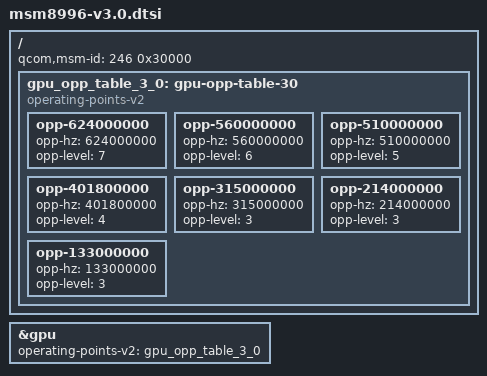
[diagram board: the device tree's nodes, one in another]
// SPDX-License-Identifier: BSD-3-Clause
/*
 * Copyright (c) 2021, Konrad Dybcio <konrad.dybcio@somainline.org>
 * Adapted for Sony Xperia X Performance (dora) MSM8996 v3.0 S1 bootloader support.
 */

/ {
	qcom,msm-id = <246 0x30000>;

	gpu_opp_table_3_0: gpu-opp-table-30 {
		compatible = "operating-points-v2";

		opp-624000000 {
			opp-hz = /bits/ 64 <624000000>;
			opp-level = <7>;
		};
		opp-560000000 {
			opp-hz = /bits/ 64 <560000000>;
			opp-level = <6>;
		};
		opp-510000000 {
			opp-hz = /bits/ 64 <510000000>;
			opp-level = <5>;
		};
		opp-401800000 {
			opp-hz = /bits/ 64 <401800000>;
			opp-level = <4>;
		};
		opp-315000000 {
			opp-hz = /bits/ 64 <315000000>;
			opp-level = <3>;
		};
		opp-214000000 {
			opp-hz = /bits/ 64 <214000000>;
			opp-level = <3>;
		};
		opp-133000000 {
			opp-hz = /bits/ 64 <133000000>;
			opp-level = <3>;
		};
	};
};

&gpu {
	operating-points-v2 = <&gpu_opp_table_3_0>;
};
